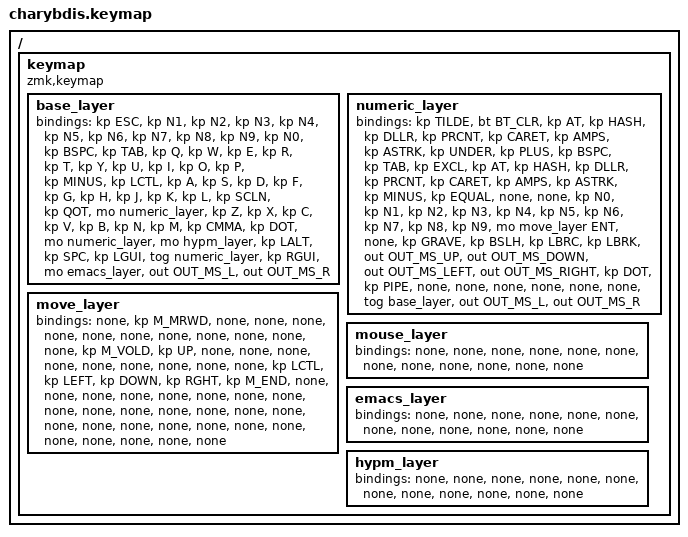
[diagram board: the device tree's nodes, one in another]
#include <behaviors.dtsi>
#include <dt-bindings/zmk/keys.h>
#include <dt-bindings/zmk/bt.h>
#include <dt-bindings/zmk/outputs.h>

/ {
    keymap {
        compatible = "zmk,keymap";

        // Base Layer (QWERTY with direct mouse clicks)
        base_layer {
            bindings = <
                &kp ESC  &kp N1  &kp N2  &kp N3  &kp N4  &kp N5    &kp N6  &kp N7  &kp N8  &kp N9  &kp N0  &kp BSPC
                &kp TAB  &kp Q   &kp W   &kp E   &kp R   &kp T     &kp Y   &kp U   &kp I   &kp O   &kp P   &kp MINUS
                &kp LCTL &kp A   &kp S   &kp D   &kp F   &kp G     &kp H   &kp J   &kp K   &kp L   &kp SCLN &kp QOT
                &mo numeric_layer &kp Z   &kp X   &kp C   &kp V &kp B  &kp N   &kp M   &kp CMMA &kp DOT &mo numeric_layer &mo hypm_layer
                         &kp LALT &kp SPC &kp LGUI           &tog numeric_layer &kp RGUI &mo emacs_layer &out OUT_MS_L &out OUT_MS_R
            >;
        };

        // Numeric Layer (Blue Layer with Bluetooth clear and mouse controls)
        numeric_layer {
            bindings = <
                &kp TILDE &bt BT_CLR &kp AT  &kp HASH &kp DLLR &kp PRCNT  &kp CARET &kp AMPS &kp ASTRK &kp UNDER &kp PLUS &kp BSPC
                &kp TAB   &kp EXCL &kp AT  &kp HASH &kp DLLR &kp PRCNT   &kp CARET &kp AMPS &kp ASTRK &kp MINUS &kp EQUAL &none
                &none     &kp N0   &kp N1  &kp N2   &kp N3   &kp N4     &kp N5    &kp N6   &kp N7    &kp N8    &kp N9    &mo move_layer ENT
                &none     &kp GRAVE &kp BSLH &kp LBRC &kp LBRK &out OUT_MS_UP &out OUT_MS_DOWN &out OUT_MS_LEFT &out OUT_MS_RIGHT &kp DOT &kp PIPE &none
                          &none    &none   &none                     &none     &none    &tog base_layer &out OUT_MS_L &out OUT_MS_R
            >;
        };

        // Move Layer (Navigation)
        move_layer {
            bindings = <
                &none &kp M_MRWD &none &none &none &none   &none &none &none &none &none &none
                &none &kp M_VOLD &kp UP   &none &none &none &none &none &none &none &none &none
                &kp LCTL &kp LEFT &kp DOWN &kp RGHT &kp M_END &none &none &none &none &none &none &none
                &none &none &none &none &none &none      &none &none &none &none &none &none
                      &none &none &none                     &none &none &none &none &none
            >;
        };

        // Mouse Layer (Deprecated, replaced by numeric layer mouse controls)
        mouse_layer {
            bindings = < &none &none &none &none &none &none &none &none &none &none &none &none >;
        };

        // Placeholder for Emacs and Hypm layers (to be expanded if needed)
        emacs_layer {
            bindings = < &none &none &none &none &none &none &none &none &none &none &none &none >;
        };
        hypm_layer {
            bindings = < &none &none &none &none &none &none &none &none &none &none &none &none >;
        };
    };
};
